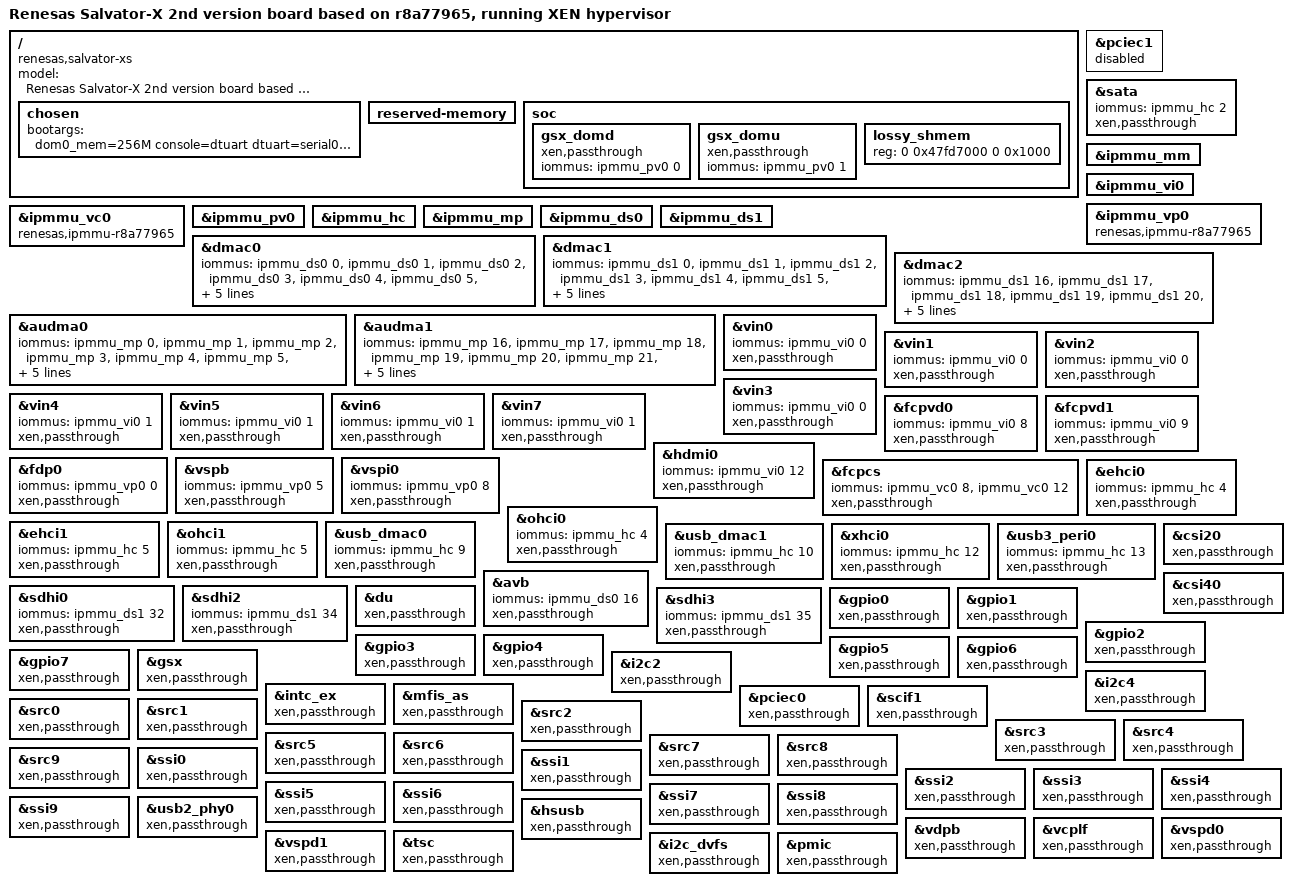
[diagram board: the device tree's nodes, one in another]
/*
 * Device Tree Source for the Salvator-X 2nd version board with R-Car M3N
 * running XEN hypervisor
 *
 * Copyright (C) 2018 Renesas Electronics Corp.
 *
 * This file is licensed under the terms of the GNU General Public License
 * version 2.  This program is licensed "as is" without any warranty of any
 * kind, whether express or implied.
 */

#include "r8a77965-salvator-xs.dts"
#include "xen-chosen.dtsi"

/ {
	model = "Renesas Salvator-X 2nd version board based on r8a77965, running XEN hypervisor";
	compatible = "renesas,salvator-xs", "renesas,r8a77965";

	chosen {
		/* Override bootargs since default "dom0_max_vcpus=4" is not appropriate for r8a77965 SoC */
		bootargs = "dom0_mem=256M console=dtuart dtuart=serial0 dom0_max_vcpus=2 bootscrub=0 loglvl=info sched_ratelimit_us=100 xsm=dummy";
	};

	reserved-memory {
		/delete-node/linux,adsp@57000000;
		/delete-node/linux,cma@58000000;
		/delete-node/linux,multimedia@70000000;
	};

	/delete-node/mmngr;
	/delete-node/mmngrbuf;

	/*
	 * When creating DT for the guest domain Xen inserts only dummy CPU nodes.
	 * And the number of these inserted CPU nodes is equal to the number of
	 * vCPUs assigned to this domain. All CPU properties which original DT has,
	 * such as OPP, clock, regulator, etc are not passed to the guest's DT.
	 *
	 * Example of guest vCPU node:
	 *
	 * cpu@0 {
	 *     device_type = "cpu";
	 *     compatible = "arm,armv8";
	 *     enable-method = "psci";
	 *     reg = <0x0>;
	 * };
	 *
	 * This results in the fact that all features expecting a57_x CPU node
	 * to be present get broken. This is why we have to explicitly
	 * remove the following.
	 */
	/delete-node/thermal-zones;
	/delete-node/pmu_a57;
};

/delete-node/&adsp;

&pciec1 {
	/* Please use exclusively to sata node */
	status = "disabled";
};

&sata {
	/* Please use exclusively to pciec1 node */
	status = "okay";
};

/* ============================ Enabled IPMMUs ===============================*/
&ipmmu_mm {
	status = "okay";
};

&ipmmu_vi0 {
	status = "okay";
};

&ipmmu_vp0 {
	compatible = "renesas,ipmmu-r8a77965";
	status = "okay";
};

&ipmmu_vc0 {
	compatible = "renesas,ipmmu-r8a77965";
	status = "okay";
};

&ipmmu_pv0 {
	status = "okay";
};

&ipmmu_hc {
	status = "okay";
};

&ipmmu_mp {
	status = "okay";
};

&ipmmu_ds0 {
	status = "okay";
};

&ipmmu_ds1 {
	status = "okay";
};

/*=========================== Bus masters linked to IPMMUS ===================*/

&dmac0 {
	iommus = <&ipmmu_ds0 0>, <&ipmmu_ds0 1>,
			 <&ipmmu_ds0 2>, <&ipmmu_ds0 3>,
			 <&ipmmu_ds0 4>, <&ipmmu_ds0 5>,
			 <&ipmmu_ds0 6>, <&ipmmu_ds0 7>,
			 <&ipmmu_ds0 8>, <&ipmmu_ds0 9>,
			 <&ipmmu_ds0 10>, <&ipmmu_ds0 11>,
			 <&ipmmu_ds0 12>, <&ipmmu_ds0 13>,
			 <&ipmmu_ds0 14>, <&ipmmu_ds0 15>;
};

&dmac1 {
	iommus = <&ipmmu_ds1 0>, <&ipmmu_ds1 1>,
			 <&ipmmu_ds1 2>, <&ipmmu_ds1 3>,
			 <&ipmmu_ds1 4>, <&ipmmu_ds1 5>,
			 <&ipmmu_ds1 6>, <&ipmmu_ds1 7>,
			 <&ipmmu_ds1 8>, <&ipmmu_ds1 9>,
			 <&ipmmu_ds1 10>, <&ipmmu_ds1 11>,
			 <&ipmmu_ds1 12>, <&ipmmu_ds1 13>,
			 <&ipmmu_ds1 14>, <&ipmmu_ds1 15>;
};

&dmac2 {
	iommus = <&ipmmu_ds1 16>, <&ipmmu_ds1 17>,
			 <&ipmmu_ds1 18>, <&ipmmu_ds1 19>,
			 <&ipmmu_ds1 20>, <&ipmmu_ds1 21>,
			 <&ipmmu_ds1 22>, <&ipmmu_ds1 23>,
			 <&ipmmu_ds1 24>, <&ipmmu_ds1 25>,
			 <&ipmmu_ds1 26>, <&ipmmu_ds1 27>,
			 <&ipmmu_ds1 28>, <&ipmmu_ds1 29>,
			 <&ipmmu_ds1 30>, <&ipmmu_ds1 31>;
};

&audma0 {
	iommus = <&ipmmu_mp 0>, <&ipmmu_mp 1>,
			 <&ipmmu_mp 2>, <&ipmmu_mp 3>,
			 <&ipmmu_mp 4>, <&ipmmu_mp 5>,
			 <&ipmmu_mp 6>, <&ipmmu_mp 7>,
			 <&ipmmu_mp 8>, <&ipmmu_mp 9>,
			 <&ipmmu_mp 10>, <&ipmmu_mp 11>,
			 <&ipmmu_mp 12>, <&ipmmu_mp 13>,
			 <&ipmmu_mp 14>, <&ipmmu_mp 15>;
};

&audma1 {
	iommus = <&ipmmu_mp 16>, <&ipmmu_mp 17>,
			 <&ipmmu_mp 18>, <&ipmmu_mp 19>,
			 <&ipmmu_mp 20>, <&ipmmu_mp 21>,
			 <&ipmmu_mp 22>, <&ipmmu_mp 23>,
			 <&ipmmu_mp 24>, <&ipmmu_mp 25>,
			 <&ipmmu_mp 26>, <&ipmmu_mp 27>,
			 <&ipmmu_mp 28>, <&ipmmu_mp 29>,
			 <&ipmmu_mp 30>, <&ipmmu_mp 31>;
};

&vin0 {
	iommus = <&ipmmu_vi0 0>;
};

&vin1 {
	iommus = <&ipmmu_vi0 0>;
};

&vin2 {
	iommus = <&ipmmu_vi0 0>;
};

&vin3 {
	iommus = <&ipmmu_vi0 0>;
};

&vin4 {
	iommus = <&ipmmu_vi0 1>;
};

&vin5 {
	iommus = <&ipmmu_vi0 1>;
};

&vin6 {
	iommus = <&ipmmu_vi0 1>;
};

&vin7 {
	iommus = <&ipmmu_vi0 1>;
};

&fcpvd0 {
	iommus = <&ipmmu_vi0 8>;
};

&fcpvd1 {
	iommus = <&ipmmu_vi0 9>;
};

&hdmi0 {
	iommus = <&ipmmu_vi0 12>;
};

&fdp0 {
	iommus = <&ipmmu_vp0 0>;
};

&vspb {
	iommus = <&ipmmu_vp0 5>;
};

&vspi0 {
	iommus = <&ipmmu_vp0 8>;
};

&sata {
	iommus = <&ipmmu_hc 2>;
};

&fcpcs {
	iommus = <&ipmmu_vc0 8>,
			 <&ipmmu_vc0 12>;
};

&ehci0 {
	iommus = <&ipmmu_hc 4>;
};

&ohci0 {
	iommus = <&ipmmu_hc 4>;
};

&ehci1 {
	iommus = <&ipmmu_hc 5>;
};

&ohci1 {
	iommus = <&ipmmu_hc 5>;
};

&usb_dmac0 {
	iommus = <&ipmmu_hc 9>;
};

&usb_dmac1 {
	iommus = <&ipmmu_hc 10>;
};

&xhci0 {
	iommus = <&ipmmu_hc 12>;
};

&usb3_peri0 {
	iommus = <&ipmmu_hc 13>;
};

&avb {
	iommus = <&ipmmu_ds0 16>;
};

&sdhi0 {
	iommus = <&ipmmu_ds1 32>;
};

&sdhi2 {
	iommus = <&ipmmu_ds1 34>;
};

&sdhi3 {
	iommus = <&ipmmu_ds1 35>;
};

/* ============================ Xen pass through section =====================*/
&csi20			{ xen,passthrough; };
&csi40			{ xen,passthrough; };
&du				{ xen,passthrough; };
&usb_dmac0		{ xen,passthrough; };
&usb_dmac1		{ xen,passthrough; };
&dmac0			{ xen,passthrough; };
&dmac1			{ xen,passthrough; };
&dmac2			{ xen,passthrough; };
&audma0			{ xen,passthrough; };
&audma1			{ xen,passthrough; };
&avb			{ xen,passthrough; };
&fdp0			{ xen,passthrough; };
&gpio0			{ xen,passthrough; };
&gpio1			{ xen,passthrough; };
&gpio2			{ xen,passthrough; };
&gpio3			{ xen,passthrough; };
&gpio4			{ xen,passthrough; };
&gpio5			{ xen,passthrough; };
&gpio6			{ xen,passthrough; };
&gpio7			{ xen,passthrough; };
&gsx			{ xen,passthrough; };
&hdmi0			{ xen,passthrough; };
&i2c2			{ xen,passthrough; };
&i2c4			{ xen,passthrough; };

/ {
	soc {
		gsx_domd {
			xen,passthrough;
			iommus = <&ipmmu_pv0 0>;
		};

		gsx_domu {
			xen,passthrough;
			iommus = <&ipmmu_pv0 1>;
		};

		lossy_shmem {
			reg = <0 0x47fd7000 0 0x1000>;
		};
	};
};

&intc_ex		{ xen,passthrough; };
&mfis_as		{ xen,passthrough; };
&sata			{ xen,passthrough; };
&pciec0			{ xen,passthrough; };
&sdhi0			{ xen,passthrough; };
&sdhi2			{ xen,passthrough; };
&sdhi3			{ xen,passthrough; };
&scif1			{ xen,passthrough; };
&src0			{ xen,passthrough; };
&src1			{ xen,passthrough; };
&src2			{ xen,passthrough; };
&src3			{ xen,passthrough; };
&src4			{ xen,passthrough; };
&src5			{ xen,passthrough; };
&src6			{ xen,passthrough; };
&src7			{ xen,passthrough; };
&src8			{ xen,passthrough; };
&src9			{ xen,passthrough; };
&ssi0			{ xen,passthrough; };
&ssi1			{ xen,passthrough; };
&ssi2			{ xen,passthrough; };
&ssi3			{ xen,passthrough; };
&ssi4			{ xen,passthrough; };
&ssi5			{ xen,passthrough; };
&ssi6			{ xen,passthrough; };
&ssi7			{ xen,passthrough; };
&ssi8			{ xen,passthrough; };
&ssi9			{ xen,passthrough; };
&usb2_phy0		{ xen,passthrough; };
&hsusb			{ xen,passthrough; };
&xhci0			{ xen,passthrough; };
&usb3_peri0		{ xen,passthrough; };
&ohci0			{ xen,passthrough; };
&ehci0			{ xen,passthrough; };
&ohci1			{ xen,passthrough; };
&ehci1			{ xen,passthrough; };
&vdpb			{ xen,passthrough; };
&vcplf			{ xen,passthrough; };
&vin0			{ xen,passthrough; };
&vin1			{ xen,passthrough; };
&vin2			{ xen,passthrough; };
&vin3			{ xen,passthrough; };
&vin4			{ xen,passthrough; };
&vin5			{ xen,passthrough; };
&vin6			{ xen,passthrough; };
&vin7			{ xen,passthrough; };
&vspd0			{ xen,passthrough; };
&vspd1			{ xen,passthrough; };
&vspb			{ xen,passthrough; };
&vspi0			{ xen,passthrough; };
&fcpvd0			{ xen,passthrough; };
&fcpvd1			{ xen,passthrough; };
&fcpcs			{ xen,passthrough; };
&tsc			{ xen,passthrough; };
&i2c_dvfs		{ xen,passthrough; };
&pmic			{ xen,passthrough; };

